# LPC5410x register map
File version: 0.4
CPU: CM4 r0p0, little endian, no MPU, no FPU, 0x3 interrupt priority bits, 0x0 interrupts
Registers are 32-bit, read-write, reset 0x0 unless marked. A register's access mark holds for its fields unless they carry their own. Offsets are from the block's base; [hi:lo] are bit positions; {n}, {i} and the like mark numbered series; 'fields as' and 'values as' point back to an identical list.

## ADC0 — 12-bit ADC controller 0
Base 0x1C034000
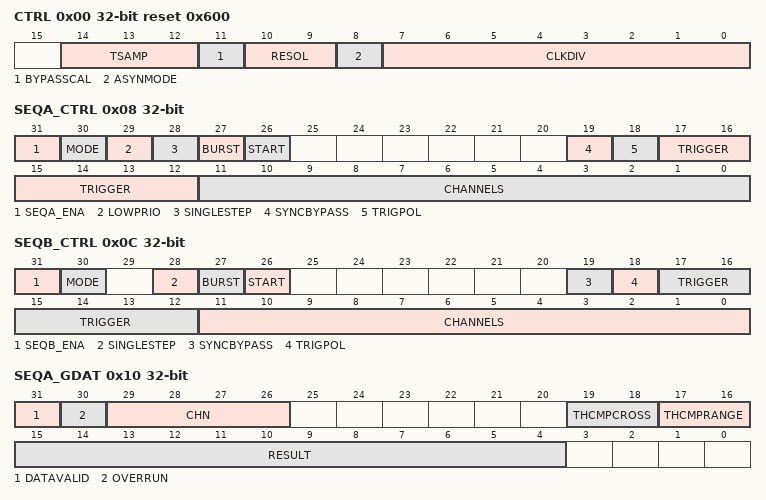
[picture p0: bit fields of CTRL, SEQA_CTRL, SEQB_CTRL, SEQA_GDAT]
0x00 CTRL reset 0x600 — ADC Control Register. Contains the clock divide value, enable bits for each sequence and the ADC power-down bit.
  [14:12] TSAMP — Sample Time. The default sampling period (TSAMP = 000) at the start of each conversion is 2.5 ADC clock periods. Depending on a variety of factors, including operating conditions and the output impedance of the analog source, longer sampling times may be required. The TSAMP field specifies the number of additional ADC clock cycles, from zero to seven, by which the sample period will be extended. The total conversion time will increase by the same number of clocks. 000 - The sample period will be the default 2.5 ADC clocks. A complete conversion with 12-bits of accuracy will require 15 clocks. 001- The sample period will be extended by one ADC clock to a total of 3.5 clock periods. A complete 12-bit conversion will require 16 clocks. 010 - The sample period will be extended by two clocks to 4.5 ADC clock cycles. A complete 12-bit conversion will require 17 ADC clocks. : 111 - The sample period will be extended by two clocks to 9.5 ADC clock cycles. A complete 12-bit conversion will require 22 ADC clocks.
  [11] BYPASSCAL — Bypass Calibration. This bit may be set to avoid the need to calibrate if offset error is not a concern in the application.
    0=CALIBRATE (Calibrate. The stored calibration value will be applied to the ADC during conversions to compensated for offset error. A calibration cycle must be performed each time the chip is powered-up. Re-calibration may be warranted periodically - especially if operating conditions have changed.); 1=BYPASS_CALIBRATION (Bypass calibration. Calibration is not utilized. Less time is required when enabling the ADC - particularly following chip power-up. Attempts to launch a calibration cycle are blocked when this bit is set.)
  [10:9] RESOL — The number of bits of ADC resolution. Accuracy can be reduced to achieve higher conversion rates. A single conversion requires the selected number of bits of resolution plus 3 ADC clocks. This field must only be altered when the ADC is fully idle. Changing it during any kind of ADC operation may have unpredictable results. ADC clock frequencies for various resolutions must not exceed: - 5x the system clock rate for 12-bit resolution - 4.3x the system clock rate for 10-bit resolution - 3.6x the system clock for 8-bit resolution - 3x the bus clock rate for 6-bit resolution
    0=6_BIT_RESOLUTION (6-bit resolution. An ADC conversion requires 9 ADC clocks, plus any clocks specified by the TSAMP field.); 1=8_BIT_RESOLUTION (8-bit resolution. An ADC conversion requires 11 ADC clocks, plus any clocks specified by the TSAMP field.); 2=10_BIT_RESOLUTION (10-bit resolution. An ADC conversion requires 13 ADC clocks, plus any clocks specified by the TSAMP field.); 3=12_BIT_RESOLUTION (12-bit resolution. An ADC conversion requires 15 ADC clocks, plus any clocks specified by the TSAMP field.)
  [8] ASYNMODE — Select clock mode.
    0=SYNCHRONOUS_MODE (Synchronous mode. The ADC clock is derived from the system clock based on the divide value selected in the CLKDIV field. The ADC clock will be started in a controlled fashion in response to a trigger to eliminate any uncertainty in the launching of an ADC conversion in response to any synchronous (on-chip) trigger. In Synchronous mode with the SYNCBYPASS bit (in a sequence control register) set, sampling of the ADC input and start of conversion will initiate 2 system clocks after the leading edge of a (synchronous) trigger pulse.); 1=ASYNCHRONOUS_MODE (Asynchronous mode. The ADC clock is based on the output of the ADC clock divider ADCCLKSEL in the SYSCON block.)
  [7:0] CLKDIV — In synchronous mode only, the system clock is divided by this value plus one to produce the clock for the ADC converter, which should be less than or equal to 80 MHz. Typically, software should program the smallest value in this field that yields this maximum clock rate or slightly less, but in certain cases (such as a high-impedance analog source) a slower clock may be desirable. This field is ignored in the asynchronous operating mode.
0x08 SEQA_CTRL — ADC Conversion Sequence-A control Register: Controls triggering and channel selection for conversion sequence-A. Also specifies interrupt mode for sequence-A.
  [31] SEQA_ENA — Sequence Enable. In order to avoid spuriously triggering the sequence, care should be taken to only set the SEQA_ENA bit when the selected trigger input is in its INACTIVE state (as defined by the TRIGPOL bit). If this condition is not met, the sequence will be triggered immediately upon being enabled. In order to avoid spuriously triggering the sequence, care should be taken to only set the SEQA_ENA bit when the selected trigger input is in its INACTIVE state (as defined by the TRIGPOL bit). If this condition is not met, the sequence will be triggered immediately upon being enabled.
    0=DISABLED (Disabled. Sequence A is disabled. Sequence A triggers are ignored. If this bit is cleared while sequence A is in progress, the sequence will be halted at the end of the current conversion. After the sequence is re-enabled, a new trigger will be required to restart the sequence beginning with the next enabled channel.); 1=ENABLED (Enabled. Sequence A is enabled.)
  [30] MODE — Indicates whether the primary method for retrieving conversion results for this sequence will be accomplished via reading the global data register (SEQA_GDAT) at the end of each conversion, or the individual channel result registers at the end of the entire sequence. Impacts when conversion-complete interrupt/DMA trigger for sequence-A will be generated and which overrun conditions contribute to an overrun interrupt as described below.
    0=END_OF_CONVERSION (End of conversion. The sequence A interrupt/DMA trigger will be set at the end of each individual ADC conversion performed under sequence A. This flag will mirror the DATAVALID bit in the SEQA_GDAT register. The OVERRUN bit in the SEQA_GDAT register will contribute to generation of an overrun interrupt/DMA trigger if enabled.); 1=END_OF_SEQUENCE (End of sequence. The sequence A interrupt/DMA trigger will be set when the entire set of sequence-A conversions completes. This flag will need to be explicitly cleared by software or by the DMA-clear signal in this mode. The OVERRUN bit in the SEQA_GDAT register will NOT contribute to generation of an overrun interrupt/DMA trigger since it is assumed this register may not be utilized in this mode.)
  [29] LOWPRIO — Set priority for sequence A.
    0=LOW_PRIORITY (Low priority. Any B trigger which occurs while an A conversion sequence is active will be ignored and lost.); 1=HIGH_PRIORITY (High priority. Setting this bit to a 1 will permit any enabled B sequence trigger (including a B sequence software start) to immediately interrupt sequence A and launch a B sequence in its place. The conversion currently in progress will be terminated. The A sequence that was interrupted will automatically resume after the B sequence completes. The channel whose conversion was terminated will be re-sampled and the conversion sequence will resume from that point.)
  [28] SINGLESTEP — When this bit is set, a hardware trigger or a write to the START bit will launch a single conversion on the next channel in the sequence instead of the default response of launching an entire sequence of conversions. Once all of the channels comprising a sequence have been converted, a subsequent trigger will repeat the sequence beginning with the first enabled channel. Interrupt generation will still occur either after each individual conversion or at the end of the entire sequence, depending on the state of the MODE bit.
  [27] BURST — Writing a 1 to this bit will cause this conversion sequence to be continuously cycled through. Other sequence A triggers will be ignored while this bit is set. Repeated conversions can be halted by clearing this bit. The sequence currently in progress will be completed before conversions are terminated. Note that a new sequence could begin just before BURST is cleared.
  [26] START — Writing a 1 to this field will launch one pass through this conversion sequence. The behavior will be identical to a sequence triggered by a hardware trigger. Do not write 1 to this bit if the BURST bit is set. This bit is only set to a 1 momentarily when written to launch a conversion sequence. It will consequently always read back as a zero.
  [19] SYNCBYPASS — Setting this bit allows the hardware trigger input to bypass synchronization flip-flop stages and therefore shorten the time between the trigger input signal and the start of a conversion. There are slightly different criteria for whether or not this bit can be set depending on the clock operating mode: Synchronous mode (the ASYNMODE in the CTRL register = 0): Synchronization may be bypassed (this bit may be set) if the selected trigger source is already synchronous with the main system clock (eg. coming from an on-chip, system-clock-based timer). Whether this bit is set or not, a trigger pulse must be maintained for at least one system clock period. Asynchronous mode (the ASYNMODE in the CTRL register = 1): Synchronization may be bypassed (this bit may be set) if it is certain that the duration of a trigger input pulse will be at least one cycle of the ADC clock (regardless of whether the trigger comes from and on-chip or off-chip source). If this bit is NOT set, the trigger pulse must at least be maintained for one system clock period.
    0=ENABLE_TRIGGER_SYNCH (Enable trigger synchronization. The hardware trigger bypass is not enabled.); 1=BYPASS_TRIGGER_SYNCH (Bypass trigger synchronization. The hardware trigger bypass is enabled.)
  [18] TRIGPOL — Select the polarity of the selected input trigger for this conversion sequence. In order to avoid generating a spurious trigger, it is recommended writing to this field only when the SEQA_ENA bit (bit 31) is low. It is safe to change this field and set bit 31 in the same write.
    0=NEGATIVE_EDGE (Negative edge. A negative edge launches the conversion sequence on the selected trigger input.); 1=POSITIVE_EDGE (Positive edge. A positive edge launches the conversion sequence on the selected trigger input.)
  [17:12] TRIGGER — Selects which of the available hardware trigger sources will cause this conversion sequence to be initiated. Program the trigger input number in this field. See Table 351. In order to avoid generating a spurious trigger, it is recommended writing to this field only when the SEQA_ENA bit (bit 31) is low. It is safe to change this field and set bit 31 in the same write.
  [11:0] CHANNELS — Selects which one or more of the ADC channels will be sampled and converted when this sequence is launched. A 1 in any bit of this field will cause the corresponding channel to be included in the conversion sequence, where bit 0 corresponds to channel 0, bit 1 to channel 1 and so forth. When this conversion sequence is triggered, either by a hardware trigger or via software command, ADC conversions will be performed on each enabled channel, in sequence, beginning with the lowest-ordered channel. This field can ONLY be changed while the SEQA_ENA bit (bit 31) is LOW. It is allowed to change this field and set bit 31 in the same write.
0x0C SEQB_CTRL — ADC Conversion Sequence-B Control Register: Controls triggering and channel selection for conversion sequence-B. Also specifies interrupt mode for sequence-B.
  [31] SEQB_ENA — Sequence Enable. In order to avoid spuriously triggering the sequence, care should be taken to only set the SEQB_ENA bit when the selected trigger input is in its INACTIVE state (as defined by the TRIGPOL bit). If this condition is not met, the sequence will be triggered immediately upon being enabled. In order to avoid spuriously triggering the sequence, care should be taken to only set the SEQB_ENA bit when the selected trigger input is in its INACTIVE state (as defined by the TRIGPOL bit). If this condition is not met, the sequence will be triggered immediately upon being enabled.
    0=DISABLED (Disabled. Sequence B is disabled. Sequence B triggers are ignored. If this bit is cleared while sequence B is in progress, the sequence will be halted at the end of the current conversion. After the sequence is re-enabled, a new trigger will be required to restart the sequence beginning with the next enabled channel.); 1=ENABLED (Enabled. Sequence B is enabled.)
  [30] MODE — Indicates whether the primary method for retrieving conversion results for this sequence will be accomplished via reading the global data register (SEQB_GDAT) at the end of each conversion, or the individual channel result registers at the end of the entire sequence. Impacts when conversion-complete interrupt/DMA trigger for sequence-B will be generated and which overrun conditions contribute to an overrun interrupt as described below.
    0=END_OF_CONVERSION (End of conversion. The sequence B interrupt/DMA trigger will be set at the end of each individual ADC conversion performed under sequence B. This flag will mirror the DATAVALID bit in the SEQB_GDAT register. The OVERRUN bit in the SEQB_GDAT register will contribute to generation of an overrun interrupt/DMA trigger if enabled.); 1=END_OF_SEQUENCE (End of sequence. The sequence B interrupt/DMA trigger will be set when the entire set of sequence-B conversions completes. This flag will need to be explicitly cleared by software or by the DMA-clear signal in this mode. The OVERRUN bit in the SEQB_GDAT register will NOT contribute to generation of an overrun interrupt/DMA trigger since it is assumed this register may not be utilized in this mode.)
  [28] SINGLESTEP — When this bit is set, a hardware trigger or a write to the START bit will launch a single conversion on the next channel in the sequence instead of the default response of launching an entire sequence of conversions. Once all of the channels comprising a sequence have been converted, a subsequent trigger will repeat the sequence beginning with the first enabled channel. Interrupt generation will still occur either after each individual conversion or at the end of the entire sequence, depending on the state of the MODE bit.
  [27] BURST — Writing a 1 to this bit will cause this conversion sequence to be continuously cycled through. Other sequence B triggers will be ignored while this bit is set. Repeated conversions can be halted by clearing this bit. The sequence currently in progress will be completed before conversions are terminated.
  [26] START — Writing a 1 to this field will launch one pass through this conversion sequence. The behavior will be identical to a sequence triggered by a hardware trigger. Do not write 1 to this bit if the BURST bit is set. This bit is only set to a 1 momentarily when written to launch a conversion sequence. It will consequently always read back as a zero.
  [19] SYNCBYPASS — Setting this bit allows the hardware trigger input to bypass synchronization flip-flop stages and therefore shorten the time between the trigger input signal and the start of a conversion. There are slightly different criteria for whether or not this bit can be set depending on the clock operating mode: Synchronous mode (the ASYNMODE in the CTRL register = 0): Synchronization may be bypassed (this bit may be set) if the selected trigger source is already synchronous with the main system clock (eg. coming from an on-chip, system-clock-based timer). Whether this bit is set or not, a trigger pulse must be maintained for at least one system clock period. Asynchronous mode (the ASYNMODE in the CTRL register = 1): Synchronization may be bypassed (this bit may be set) if it is certain that the duration of a trigger input pulse will be at least one cycle of the ADC clock (regardless of whether the trigger comes from and on-chip or off-chip source). If this bit is NOT set, the trigger pulse must at least be maintained for one system clock period.
    0=ENABLE_SYNCHRONIZATI (Enable synchronization. The hardware trigger bypass is not enabled.); 1=BYPASS_SYNCHRONIZATI (Bypass synchronization. The hardware trigger bypass is enabled.)
  [18] TRIGPOL — Select the polarity of the selected input trigger for this conversion sequence. In order to avoid generating a spurious trigger, it is recommended writing to this field only when the SEQB_ENA bit (bit 31) is low. It is safe to change this field and set bit 31 in the same write.
    values as SEQA_CTRL.TRIGPOL
  [17:12] TRIGGER — Selects which of the available hardware trigger sources will cause this conversion sequence to be initiated. Program the trigger input number in this field. See Table 351. In order to avoid generating a spurious trigger, it is recommended writing to this field only when the SEQB_ENA bit (bit 31) is low. It is safe to change this field and set bit 31 in the same write.
  [11:0] CHANNELS — Selects which one or more of the ADC channels will be sampled and converted when this sequence is launched. A 1 in any bit of this field will cause the corresponding channel to be included in the conversion sequence, where bit 0 corresponds to channel 0, bit 1 to channel 1 and so forth. When this conversion sequence is triggered, either by a hardware trigger or via software command, ADC conversions will be performed on each enabled channel, in sequence, beginning with the lowest-ordered channel. This field can ONLY be changed while the SEQB_ENA bit (bit 31) is LOW. It is allowed to change this field and set bit 31 in the same write.
0x10 SEQA_GDAT ro reset not defined — ADC Sequence-A Global Data Register. This register contains the result of the most recent ADC conversion performed under sequence-A
  [31] DATAVALID — This bit is set to 1 at the end of each conversion when a new result is loaded into the RESULT field. It is cleared whenever this register is read. This bit will cause a conversion-complete interrupt for the corresponding sequence if the MODE bit (in SEQA_CTRL) for that sequence is set to 0 (and if the interrupt is enabled).
  [30] OVERRUN — This bit is set if a new conversion result is loaded into the RESULT field before a previous result has been read - i.e. while the DATAVALID bit is set. This bit is cleared, along with the DATAVALID bit, whenever this register is read. This bit will contribute to an overrun interrupt/DMA trigger if the MODE bit (in SEQAA_CTRL) for the corresponding sequence is set to 0 (and if the overrun interrupt is enabled).
  [29:26] CHN — These bits contain the channel from which the RESULT bits were converted (e.g. 0000 identifies channel 0, 0001 channel 1, etc.).
  [19:18] THCMPCROSS — Indicates whether the result of the last conversion performed represented a crossing of the threshold level established by the designated LOW threshold comparison register (THRn_LOW) and, if so, in what direction the crossing occurred.
  [17:16] THCMPRANGE — Indicates whether the result of the last conversion performed was above, below or within the range established by the designated threshold comparison registers (THRn_LOW and THRn_HIGH).
  [15:4] RESULT — This field contains the 12-bit ADC conversion result from the most recent conversion performed under conversion sequence associated with this register. The result is a binary fraction representing the voltage on the currently-selected input channel as it falls within the range of VREFP to VREFN. Zero in the field indicates that the voltage on the input pin was less than, equal to, or close to that on VREFN, while 0xFFF indicates that the voltage on the input was close to, equal to, or greater than that on VREFP. DATAVALID = 1 indicates that this result has not yet been read.
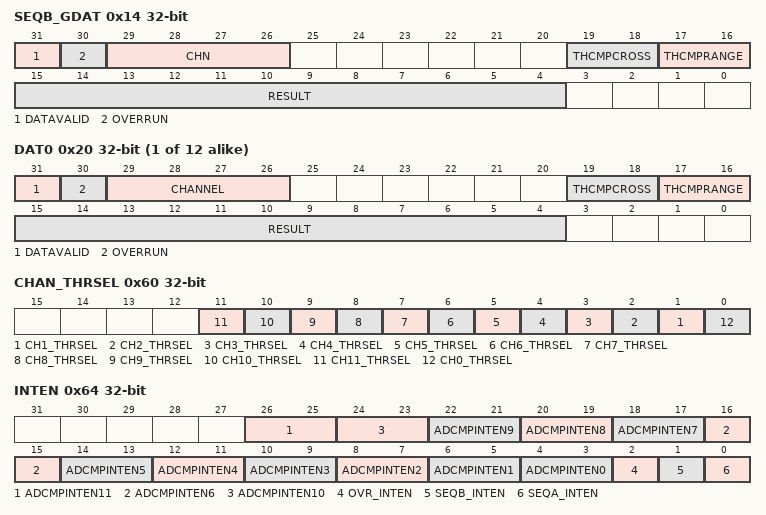
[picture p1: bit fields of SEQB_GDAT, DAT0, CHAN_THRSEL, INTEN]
0x14 SEQB_GDAT ro reset not defined — ADC Sequence-B Global Data Register. This register contains the result of the most recent ADC conversion performed under sequence-B
  [31] DATAVALID — This bit is set to 1 at the end of each conversion when a new result is loaded into the RESULT field. It is cleared whenever this register is read. This bit will cause a conversion-complete interrupt for the corresponding sequence if the MODE bit (in SEQB_CTRL) for that sequence is set to 0 (and if the interrupt is enabled).
  [30] OVERRUN — This bit is set if a new conversion result is loaded into the RESULT field before a previous result has been read - i.e. while the DATAVALID bit is set. This bit is cleared, along with the DATAVALID bit, whenever this register is read. This bit will contribute to an overrun interrupt/DMA trigger if the MODE bit (in SEQB_CTRL) for the corresponding sequence is set to 0 (and if the overrun interrupt is enabled).
  [29:26] CHN — These bits contain the channel from which the RESULT bits were converted (e.g. 0000 identifies channel 0, 0001 channel 1, etc.).
  [19:18] THCMPCROSS — Indicates whether the result of the last conversion performed represented a crossing of the threshold level established by the designated LOW threshold comparison register (THRn_LOW) and, if so, in what direction the crossing occurred.
  [17:16] THCMPRANGE — Indicates whether the result of the last conversion performed was above, below or within the range established by the designated threshold comparison registers (THRn_LOW and THRn_HIGH).
  [15:4] RESULT — This field contains the 12-bit ADC conversion result from the most recent conversion performed under conversion sequence associated with this register. The result is a binary fraction representing the voltage on the currently-selected input channel as it falls within the range of VREFP to VREFN. Zero in the field indicates that the voltage on the input pin was less than, equal to, or close to that on VREFN, while 0xFFF indicates that the voltage on the input was close to, equal to, or greater than that on VREFP. DATAVALID = 1 indicates that this result has not yet been read.
{0x20+4i} DAT{i} ro reset not defined (i=0..11) — ADC Channel 0 Data Register. This register contains the result of the most recent conversion completed on channel 0.
  [31] DATAVALID — This bit is set to 1 when an ADC conversion on this channel completes. This bit is cleared whenever this register is read or when the data related to this channel is read from either of the global SEQn_GDAT registers. While it is allowed to include the same channels in both conversion sequences, doing so may cause erratic behavior of the DONE and OVERRUN bits in the data registers associated with any of the channels that are shared between the two sequences. Any erratic OVERRUN behavior will also affect overrun interrupt generation, if enabled.
  [30] OVERRUN — This bit will be set to a 1 if a new conversion on this channel completes and overwrites the previous contents of the RESULT field before it has been read - i.e. while the DONE bit is set. This bit is cleared, along with the DONE bit, whenever this register is read or when the data related to this channel is read from either of the global SEQn_GDAT registers. This bit (in any of the 12 registers) will cause an overrun interrupt/DMA trigger to be asserted if the overrun interrupt is enabled. While it is allowed to include the same channels in both conversion sequences, doing so may cause erratic behavior of the DONE and OVERRUN bits in the data registers associated with any of the channels that are shared between the two sequences. Any erratic OVERRUN behavior will also affect overrun interrupt generation, if enabled.
  [29:26] CHANNEL — This field is hard-coded to contain the channel number that this particular register relates to (i.e. this field will contain 0b0000 for the DAT0 register, 0b0001 for the DAT1 register, etc)
  [19:18] THCMPCROSS — Threshold Crossing Comparison result. 0x0 = No threshold Crossing detected: The most recent completed conversion on this channel had the same relationship (above or below) to the threshold value established by the designated LOW threshold register (THRn_LOW) as did the previous conversion on this channel. 0x1 = Reserved. 0x2 = Downward Threshold Crossing Detected. Indicates that a threshold crossing in the downward direction has occurred - i.e. the previous sample on this channel was above the threshold value established by the designated LOW threshold register (THRn_LOW) and the current sample is below that threshold. 0x3 = Upward Threshold Crossing Detected. Indicates that a threshold crossing in the upward direction has occurred - i.e. the previous sample on this channel was below the threshold value established by the designated LOW threshold register (THRn_LOW) and the current sample is above that threshold.
  [17:16] THCMPRANGE — Threshold Range Comparison result. 0x0 = In Range: The last completed conversion was greater than or equal to the value programmed into the designated LOW threshold register (THRn_LOW) but less than or equal to the value programmed into the designated HIGH threshold register (THRn_HIGH). 0x1 = Below Range: The last completed conversion on was less than the value programmed into the designated LOW threshold register (THRn_LOW). 0x2 = Above Range: The last completed conversion was greater than the value programmed into the designated HIGH threshold register (THRn_HIGH). 0x3 = Reserved.
  [15:4] RESULT — This field contains the 12-bit ADC conversion result from the last conversion performed on this channel. This will be a binary fraction representing the voltage on the AD0[n] pin, as it falls within the range of VREFP to VREFN. Zero in the field indicates that the voltage on the input pin was less than, equal to, or close to that on VREFN, while 0xFFF indicates that the voltage on the input was close to, equal to, or greater than that on VREFP.
0x50 THR0_LOW — ADC Low Compare Threshold Register 0: Contains the lower threshold level for automatic threshold comparison for any channels linked to threshold pair 0.
  [15:4] THRLOW — Low threshold value against which ADC results will be compared
0x54 THR1_LOW — ADC Low Compare Threshold Register 1: Contains the lower threshold level for automatic threshold comparison for any channels linked to threshold pair 1.
  fields as THR0_LOW
0x58 THR0_HIGH — ADC High Compare Threshold Register 0: Contains the upper threshold level for automatic threshold comparison for any channels linked to threshold pair 0.
  [15:4] THRHIGH — High threshold value against which ADC results will be compared
0x5C THR1_HIGH — ADC High Compare Threshold Register 1: Contains the upper threshold level for automatic threshold comparison for any channels linked to threshold pair 1.
  fields as THR0_HIGH
0x60 CHAN_THRSEL — ADC Channel-Threshold Select Register. Specifies which set of threshold compare registers are to be used for each channel
  [n] CH{n}_THRSEL (n=1..11) — Threshold select for channel {n}. See description for channel 0.
  [0] CH0_THRSEL — Threshold select for channel 0.
    0=THRESHOLD0 (Threshold 0. Results for this channel will be compared against the threshold levels indicated in the THR0_LOW and THR0_HIGH registers.); 1=THRESHOLD1 (Threshold 1. Results for this channel will be compared against the threshold levels indicated in the THR1_LOW and THR1_HIGH registers.)
0x64 INTEN — ADC Interrupt Enable Register. This register contains enable bits that enable the sequence-A, sequence-B, threshold compare and data overrun interrupts to be generated.
  [26:25] ADCMPINTEN11 — Channel 21 threshold comparison interrupt enable. See description for channel 0.
  [2n+4:2n+3] ADCMPINTEN{n} (n=1..10) — Channel {n} threshold comparison interrupt enable. See description for channel 0.
  [4:3] ADCMPINTEN0 — Threshold comparison interrupt enable for channel 0.
    0=DISABLED; 1=OUTSIDE_THRESHOLD; 2=CROSSING_THRESHOLD
  [2] OVR_INTEN — Overrun interrupt enable.
    0=DISABLED (Disabled. The overrun interrupt is disabled.); 1=ENABLED (Enabled. The overrun interrupt is enabled. Detection of an overrun condition on any of the 12 channel data registers will cause an overrun interrupt/DMA trigger. In addition, if the MODE bit for a particular sequence is 0, then an overrun in the global data register for that sequence will also cause this interrupt/DMA trigger to be asserted.)
  [1] SEQB_INTEN — Sequence B interrupt enable.
    0=DISABLED (Disabled. The sequence B interrupt/DMA trigger is disabled.); 1=ENABLED (Enabled. The sequence B interrupt/DMA trigger is enabled and will be asserted either upon completion of each individual conversion performed as part of sequence B, or upon completion of the entire B sequence of conversions, depending on the MODE bit in the SEQB_CTRL register.)
  [0] SEQA_INTEN — Sequence A interrupt enable.
    0=DISABLED (Disabled. The sequence A interrupt/DMA trigger is disabled.); 1=ENABLED (Enabled. The sequence A interrupt/DMA trigger is enabled and will be asserted either upon completion of each individual conversion performed as part of sequence A, or upon completion of the entire A sequence of conversions, depending on the MODE bit in the SEQA_CTRL register.)
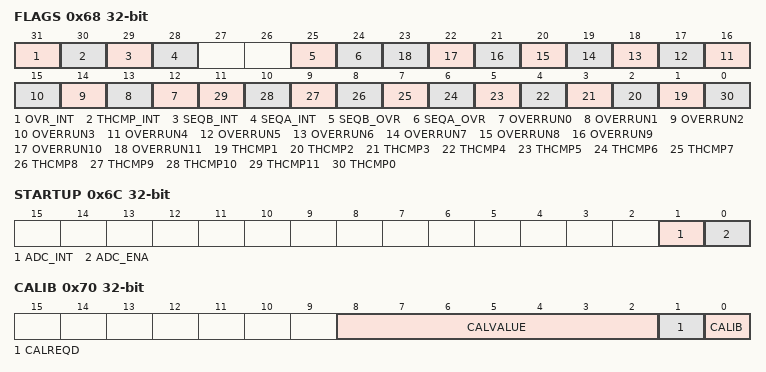
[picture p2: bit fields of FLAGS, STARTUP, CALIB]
0x68 FLAGS ro — ADC Flags Register. Contains the four interrupt/DMA trigger flags and the individual component overrun and threshold-compare flags. (The overrun bits replicate information stored in the result registers).
  [31] OVR_INT — Overrun Interrupt flag. Any overrun bit in any of the individual channel data registers will cause this interrupt. In addition, if the MODE bit in either of the SEQn_CTRL registers is 0 then the OVERRUN bit in the corresponding SEQn_GDAT register will also cause this interrupt. This interrupt must be enabled in the INTEN register. This bit will be cleared when all of the individual overrun bits have been cleared via reading the corresponding data registers.
  [30] THCMP_INT — Threshold Comparison Interrupt. This bit will be set if any of the THCMP flags in the lower bits of this register are set to 1 (due to an enabled out-of-range or threshold-crossing event on any channel). Each type of threshold comparison interrupt on each channel must be individually enabled in the INTEN register to cause this interrupt. This bit will be cleared when all of the individual threshold flags are cleared via writing 1s to those bits.
  [29] SEQB_INT — Sequence A interrupt/DMA trigger. If the MODE bit in the SEQB_CTRL register is 0, this flag will mirror the DATAVALID bit in the sequence A global data register (SEQB_GDAT), which is set at the end of every ADC conversion performed as part of sequence B. It will be cleared automatically when the SEQB_GDAT register is read. If the MODE bit in the SEQB_CTRL register is 1, this flag will be set upon completion of an entire B sequence. In this case it must be cleared by writing a 1 to this SEQB_INT bit. This interrupt must be enabled in the INTEN register.
  [28] SEQA_INT — Sequence A interrupt/DMA trigger. If the MODE bit in the SEQA_CTRL register is 0, this flag will mirror the DATAVALID bit in the sequence A global data register (SEQA_GDAT), which is set at the end of every ADC conversion performed as part of sequence A. It will be cleared automatically when the SEQA_GDAT register is read. If the MODE bit in the SEQA_CTRL register is 1, this flag will be set upon completion of an entire A sequence. In this case it must be cleared by writing a 1 to this SEQA_INT bit. This interrupt must be enabled in the INTEN register.
  [25] SEQB_OVR — Mirrors the global OVERRUN status flag in the SEQB_GDAT register
  [24] SEQA_OVR — Mirrors the global OVERRUN status flag in the SEQA_GDAT register
  [n+12] OVERRUN{n} (n=0..11) — Mirrors the OVERRRUN status flag from the result register for ADC channel {n}
  [n] THCMP{n} (n=1..11) — Threshold comparison event on Channel {n}. See description for channel 0.
  [0] THCMP0 — Threshold comparison event on Channel 0. Set to 1 upon either an out-of-range result or a threshold-crossing result if enabled to do so in the INTEN register. This bit is cleared by writing a 1.
0x6C STARTUP — ADC Startup Register (typically only used by the ADC API).
  [1] ADC_INT
  [0] ADC_ENA — ADC Enable bit. This bit can only be set to a 1 by software. It is cleared automatically whenever the ADC is powered down. This bit must not be set until at least 10 microseconds after the ADC is powered up (typically by altering a system-level ADC power control bit).
0x70 CALIB — ADC Calibration Register.
  [8:2] CALVALUE — Calibration Value. This read-only field displays the calibration value established during last calibration cycle. This value is not typically of any use to the user.
  [1] CALREQD — Calibration required. This read-only bit indicates if calibration is required when enabling the ADC. CALREQD will be 1 if no calibration has been run since the chip was powered-up and if the BYPASSCAL bit in the ADCTRL register is low. The ADC API will test this bit to determine whether to initiate a calibration cycle or whether to set the ADC_INIT bit (in the ADSTARTUP register) to launch the ADC initialization process which includes a dummy conversion cycle. Note: A dummy conversion cycle requires approximately 6 ADC clocks as opposed to 81 clocks required for calibration.
  [0] CALIB — Calibration request. Setting this bit will launch an ADC calibration cycle. This bit can only be set to a 1 by software. It is cleared automatically when the calibration cycle completes.
